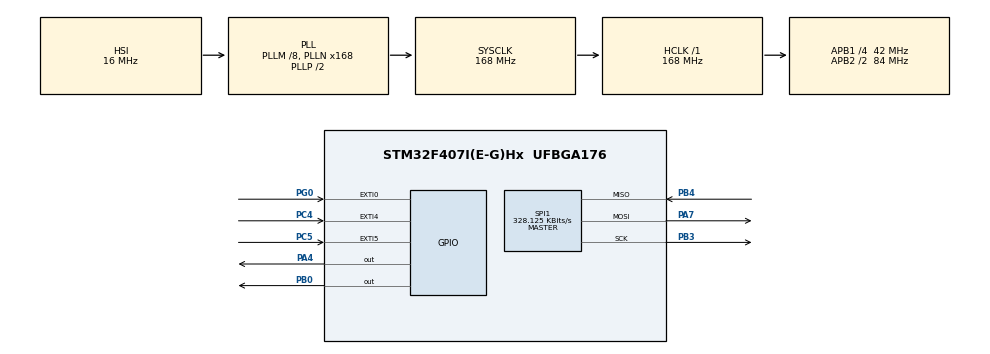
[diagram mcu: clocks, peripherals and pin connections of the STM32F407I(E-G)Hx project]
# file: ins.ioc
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Dma.Request0=SPI1_RX
Dma.Request1=SPI1_TX
Dma.SPI1_RX.0.Direction=DMA_PERIPH_TO_MEMORY
Dma.SPI1_RX.0.FIFOMode=DMA_FIFOMODE_DISABLE
Dma.SPI1_RX.0.Instance=DMA2_Stream2
Dma.SPI1_RX.0.MemDataAlignment=DMA_MDATAALIGN_BYTE
Dma.SPI1_RX.0.MemInc=DMA_MINC_ENABLE
Dma.SPI1_RX.0.Mode=DMA_NORMAL
Dma.SPI1_RX.0.PeriphDataAlignment=DMA_PDATAALIGN_BYTE
Dma.SPI1_RX.0.PeriphInc=DMA_PINC_DISABLE
Dma.SPI1_RX.0.Priority=DMA_PRIORITY_VERY_HIGH
Dma.SPI1_TX.1.Direction=DMA_MEMORY_TO_PERIPH
Dma.SPI1_TX.1.FIFOMode=DMA_FIFOMODE_DISABLE
Dma.SPI1_TX.1.Instance=DMA2_Stream3
Dma.SPI1_TX.1.MemDataAlignment=DMA_MDATAALIGN_BYTE
Dma.SPI1_TX.1.MemInc=DMA_MINC_ENABLE
Dma.SPI1_TX.1.Mode=DMA_NORMAL
Dma.SPI1_TX.1.PeriphDataAlignment=DMA_PDATAALIGN_BYTE
Dma.SPI1_TX.1.PeriphInc=DMA_PINC_DISABLE
Dma.SPI1_TX.1.Priority=DMA_PRIORITY_HIGH
FREERTOS.INCLUDE_eTaskGetState=1
FREERTOS.INCLUDE_pcTaskGetTaskName=1
FREERTOS.INCLUDE_uxTaskGetStackHighWaterMark=1
FREERTOS.INCLUDE_vTaskCleanUpResources=1
FREERTOS.INCLUDE_vTaskDelayUntil=1
FREERTOS.INCLUDE_xQueueGetMutexHolder=1
FREERTOS.INCLUDE_xSemaphoreGetMutexHolder=1
FREERTOS.INCLUDE_xTaskAbortDelay=1
FREERTOS.INCLUDE_xTaskGetCurrentTaskHandle=1
FREERTOS.INCLUDE_xTaskGetHandle=1
FREERTOS.Tasks01=defaultTask,0,128,StartDefaultTask,Default,NULL,Dynamic,NULL,NULL;INSTask,3,128,ins_task,As external,NULL,Dynamic,NULL,NULL
FREERTOS.configUSE_TIMERS=0
Mcu.Family=STM32F4
Mcu.Name=STM32F407I(E-G)Hx
Mcu.Package=UFBGA176
NVIC.DMA2_Stream2_IRQn=true\:5\:0\:false\:false\:false\:true\:false\:true\:true
NVIC.DMA2_Stream3_IRQn=true\:5\:0\:false\:false\:false\:true\:false\:true\:true
NVIC.EXTI0_IRQn=true\:5\:0\:false\:false\:true\:true\:true\:true\:true
NVIC.EXTI4_IRQn=true\:5\:0\:false\:false\:true\:true\:true\:true\:true
NVIC.EXTI9_5_IRQn=true\:5\:0\:false\:false\:true\:true\:true\:true\:true
NVIC.PriorityGroup=NVIC_PRIORITYGROUP_4
PA4.GPIO_PuPd=GPIO_PULLUP
PA4.PinState=GPIO_PIN_SET
PA4.Signal=GPIO_Output
PA7.GPIO_PuPd=GPIO_PULLUP
PA7.Mode=Full_Duplex_Master
PA7.Signal=SPI1_MOSI
PB0.GPIO_PuPd=GPIO_PULLUP
PB0.PinState=GPIO_PIN_SET
PB0.Signal=GPIO_Output
PB3.GPIO_PuPd=GPIO_PULLUP
PB3.Mode=Full_Duplex_Master
PB3.Signal=SPI1_SCK
PB4.GPIO_PuPd=GPIO_PULLUP
PB4.Mode=Full_Duplex_Master
PB4.Signal=SPI1_MISO
PC14-OSC32_IN.Mode=LSE-External-Oscillator
PC14-OSC32_IN.Signal=RCC_OSC32_IN
PC15-OSC32_OUT.Mode=LSE-External-Oscillator
PC15-OSC32_OUT.Signal=RCC_OSC32_OUT
PC4.GPIO_PuPd=GPIO_PULLUP
PC4.Signal=GPXTI4
PC5.GPIO_PuPd=GPIO_PULLUP
PC5.Signal=GPXTI5
PG0.GPIO_PuPd=GPIO_PULLUP
PG0.Signal=GPXTI0
PH0-OSC_IN.Mode=HSE-External-Oscillator
PH0-OSC_IN.Signal=RCC_OSC_IN
PH1-OSC_OUT.Mode=HSE-External-Oscillator
PH1-OSC_OUT.Signal=RCC_OSC_OUT
ProjectManager.HeapSize=0x200
ProjectManager.StackSize=0x400
ProjectManager.TargetToolchain=CMake
RCC.48MHZClocksFreq_Value=84000000
RCC.AHBFreq_Value=168000000
RCC.APB1CLKDivider=RCC_HCLK_DIV4
RCC.APB1Freq_Value=42000000
RCC.APB1TimFreq_Value=84000000
RCC.APB2CLKDivider=RCC_HCLK_DIV2
RCC.APB2Freq_Value=84000000
RCC.APB2TimFreq_Value=168000000
RCC.CortexFreq_Value=168000000
RCC.HCLKFreq_Value=168000000
RCC.HSE_VALUE=25000000
RCC.HSI_VALUE=16000000
RCC.PLLM=8
RCC.PLLN=168
RCC.SYSCLKFreq_VALUE=168000000
RCC.SYSCLKSource=RCC_SYSCLKSOURCE_PLLCLK
RCC.VCOOutputFreq_Value=336000000
SPI1.BaudRatePrescaler=SPI_BAUDRATEPRESCALER_256
SPI1.CLKPhase=SPI_PHASE_2EDGE
SPI1.CLKPolarity=SPI_POLARITY_HIGH
SPI1.CalculateBaudRate=328.125 KBits/s
SPI1.Direction=SPI_DIRECTION_2LINES
SPI1.Mode=SPI_MODE_MASTER
SPI1.VirtualType=VM_MASTER
VP_FREERTOS_VS_CMSIS_V1.Mode=CMSIS_V1
board=custom

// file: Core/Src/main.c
/* USER CODE BEGIN Header */
/**
  ******************************************************************************
  * @file           : main.c
  * @brief          : Main program body
  ******************************************************************************
  * @attention
  *
  * Copyright (c) 2024 STMicroelectronics.
  * All rights reserved.
  *
  * This software is licensed under terms that can be found in the LICENSE file
  * in the root directory of this software component.
  * If no LICENSE file comes with this software, it is provided AS-IS.
  *
  ******************************************************************************
  */
/* USER CODE END Header */
#include "main.h"
#include "cmsis_os.h"
#include "dma.h"
#include "spi.h"
#include "gpio.h"

/* USER CODE BEGIN Includes */
#include "bsp_delay.h"
/* USER CODE END Includes */

void SystemClock_Config(void);
void MX_FREERTOS_Init(void);

int main(void)
{

  /* MCU Configuration--------------------------------------------------------*/

  /* Reset of all peripherals, Initializes the Flash interface and the Systick. */
  HAL_Init();

  /* Configure the system clock */
  SystemClock_Config();

  /* Initialize all configured peripherals */
  MX_GPIO_Init();
  MX_DMA_Init();
  MX_SPI1_Init();
  /* USER CODE BEGIN 2 */
  delay_init();
  /* USER CODE END 2 */

  /* Call init function for freertos objects (in cmsis_os2.c) */
  MX_FREERTOS_Init();

  /* Start scheduler */
  osKernelStart();

  /* We should never get here as control is now taken by the scheduler */

  /* Infinite loop */
  while (1)
  {

  }
}

void SystemClock_Config(void)
{
  RCC_OscInitTypeDef RCC_OscInitStruct = {0};
  RCC_ClkInitTypeDef RCC_ClkInitStruct = {0};

  /** Configure the main internal regulator output voltage
  */
  __HAL_RCC_PWR_CLK_ENABLE();
  __HAL_PWR_VOLTAGESCALING_CONFIG(PWR_REGULATOR_VOLTAGE_SCALE1);

  /** Initializes the RCC Oscillators according to the specified parameters
  * in the RCC_OscInitTypeDef structure.
  */
  RCC_OscInitStruct.OscillatorType = RCC_OSCILLATORTYPE_HSI;
  RCC_OscInitStruct.HSIState = RCC_HSI_ON;
  RCC_OscInitStruct.HSICalibrationValue = RCC_HSICALIBRATION_DEFAULT;
  RCC_OscInitStruct.PLL.PLLState = RCC_PLL_ON;
  RCC_OscInitStruct.PLL.PLLSource = RCC_PLLSOURCE_HSI;
  RCC_OscInitStruct.PLL.PLLM = 8;
  RCC_OscInitStruct.PLL.PLLN = 168;
  RCC_OscInitStruct.PLL.PLLP = RCC_PLLP_DIV2;
  RCC_OscInitStruct.PLL.PLLQ = 4;
  if (HAL_RCC_OscConfig(&RCC_OscInitStruct) != HAL_OK)
  {
    Error_Handler();
  }

  /** Initializes the CPU, AHB and APB buses clocks
  */
  RCC_ClkInitStruct.ClockType = RCC_CLOCKTYPE_HCLK|RCC_CLOCKTYPE_SYSCLK
                              |RCC_CLOCKTYPE_PCLK1|RCC_CLOCKTYPE_PCLK2;
  RCC_ClkInitStruct.SYSCLKSource = RCC_SYSCLKSOURCE_PLLCLK;
  RCC_ClkInitStruct.AHBCLKDivider = RCC_SYSCLK_DIV1;
  RCC_ClkInitStruct.APB1CLKDivider = RCC_HCLK_DIV4;
  RCC_ClkInitStruct.APB2CLKDivider = RCC_HCLK_DIV2;

  if (HAL_RCC_ClockConfig(&RCC_ClkInitStruct, FLASH_LATENCY_5) != HAL_OK)
  {
    Error_Handler();
  }
}

void Error_Handler(void)
{
  __disable_irq();
  while (1)
  {
  }
}

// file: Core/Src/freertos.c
/* USER CODE BEGIN Header */
/**
  ******************************************************************************
  * File Name          : freertos.c
  * Description        : Code for freertos applications
  ******************************************************************************
  * @attention
  *
  * Copyright (c) 2024 STMicroelectronics.
  * All rights reserved.
  *
  * This software is licensed under terms that can be found in the LICENSE file
  * in the root directory of this software component.
  * If no LICENSE file comes with this software, it is provided AS-IS.
  *
  ******************************************************************************
  */
/* USER CODE END Header */

#include "FreeRTOS.h"
#include "task.h"
#include "main.h"
#include "cmsis_os.h"

osThreadId defaultTaskHandle;
osThreadId INSTaskHandle;

void StartDefaultTask(void const * argument);
extern void ins_task(void const * argument);

void MX_FREERTOS_Init(void); /* (MISRA C 2004 rule 8.1) */

/* GetIdleTaskMemory prototype (linked to static allocation support) */
void vApplicationGetIdleTaskMemory( StaticTask_t **ppxIdleTaskTCBBuffer, StackType_t **ppxIdleTaskStackBuffer, uint32_t *pulIdleTaskStackSize );

/* USER CODE BEGIN GET_IDLE_TASK_MEMORY */
static StaticTask_t xIdleTaskTCBBuffer;
static StackType_t xIdleStack[configMINIMAL_STACK_SIZE];

void vApplicationGetIdleTaskMemory( StaticTask_t **ppxIdleTaskTCBBuffer, StackType_t **ppxIdleTaskStackBuffer, uint32_t *pulIdleTaskStackSize )
{
  *ppxIdleTaskTCBBuffer = &xIdleTaskTCBBuffer;
  *ppxIdleTaskStackBuffer = &xIdleStack[0];
  *pulIdleTaskStackSize = configMINIMAL_STACK_SIZE;
  /* place for user code */
}
/* USER CODE END GET_IDLE_TASK_MEMORY */

void MX_FREERTOS_Init(void) {

  /* Create the thread(s) */
  /* definition and creation of defaultTask */
  osThreadDef(defaultTask, StartDefaultTask, osPriorityNormal, 0, 128);
  defaultTaskHandle = osThreadCreate(osThread(defaultTask), NULL);

  /* definition and creation of INSTask */
  osThreadDef(INSTask, ins_task, osPriorityRealtime, 0, 128);
  INSTaskHandle = osThreadCreate(osThread(INSTask), NULL);

}

void StartDefaultTask(void const * argument)
{
  /* USER CODE BEGIN StartDefaultTask */
  /* Infinite loop */
  for(;;)
  {
    osDelay(10);
  }
  /* USER CODE END StartDefaultTask */
}
